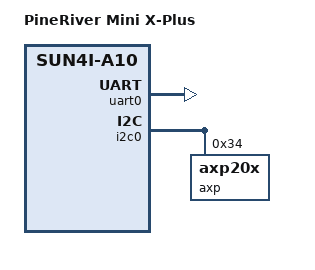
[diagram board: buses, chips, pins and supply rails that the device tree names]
/*
 * Copyright 2012 Maxime Ripard
 *
 * Maxime Ripard <maxime.ripard@free-electrons.com>
 *
 * The code contained herein is licensed under the GNU General Public
 * License. You may obtain a copy of the GNU General Public License
 * Version 2 or later at the following locations:
 *
 * http://www.opensource.org/licenses/gpl-license.html
 * http://www.gnu.org/copyleft/gpl.html
 */

/dts-v1/;
/include/ "sun4i-a10.dtsi"

/ {
	model = "PineRiver Mini X-Plus";
	compatible = "pineriver,mini-xplus", "allwinner,sun4i-a10";

	soc@01c00000 {
		uart0: serial@01c28000 {
			pinctrl-names = "default";
			pinctrl-0 = <&uart0_pins_a>;
			status = "okay";
		};

		i2c0: i2c@01c2ac00 {
			pinctrl-names = "default";
			pinctrl-0 = <&i2c0_pins_a>;
			status = "okay";

			axp: axp20x@34 {
				reg = <0x34>;
				interrupts = <0>;

				/include/ "x-powers-axp209.dtsi"
			};
		};
	};
};
